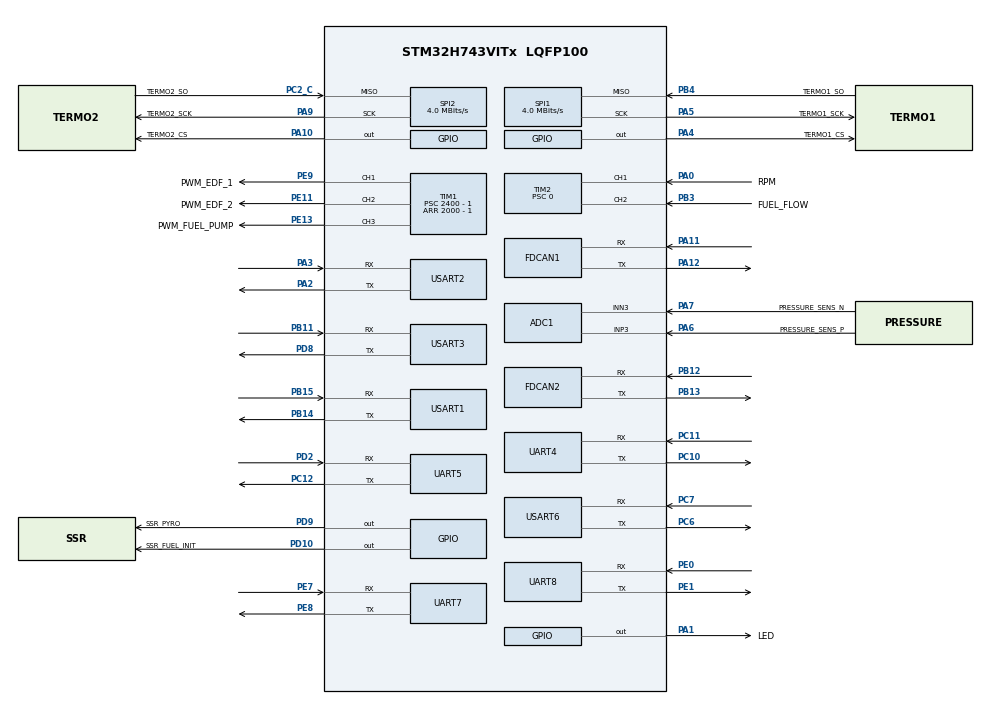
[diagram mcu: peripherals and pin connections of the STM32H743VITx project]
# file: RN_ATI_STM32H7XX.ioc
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ADC1.AutoInjectedConv-ADC_Injected_ConversionMode=DISABLE
ADC1.Channel-1\#ChannelRegularConversion=ADC_CHANNEL_3
ADC1.NbrOfConversionFlag=1
ADC1.OffsetNumber-1\#ChannelRegularConversion=ADC_OFFSET_NONE
ADC1.OffsetSignedSaturation-1\#ChannelRegularConversion=DISABLE
ADC1.Rank-1\#ChannelRegularConversion=1
ADC1.SamplingTime-1\#ChannelRegularConversion=ADC_SAMPLETIME_1CYCLE_5
ADC1.ScanConvMode-ADC_Settings=ADC_SCAN_ENABLE
ADC1.SingleDiff-1\#ChannelRegularConversion=ADC_DIFFERENTIAL_ENDED
ADC1.master=1
CORTEX_M7.default_mode_Activation=1
Dma.Request0=TIM1_CH1
Dma.Request1=TIM1_CH2
Dma.Request2=TIM1_CH3
Dma.TIM1_CH1.0.Direction=DMA_MEMORY_TO_PERIPH
Dma.TIM1_CH1.0.EventEnable=DISABLE
Dma.TIM1_CH1.0.FIFOMode=DMA_FIFOMODE_DISABLE
Dma.TIM1_CH1.0.Instance=DMA1_Stream0
Dma.TIM1_CH1.0.MemDataAlignment=DMA_MDATAALIGN_HALFWORD
Dma.TIM1_CH1.0.MemInc=DMA_MINC_ENABLE
Dma.TIM1_CH1.0.Mode=DMA_NORMAL
Dma.TIM1_CH1.0.PeriphDataAlignment=DMA_PDATAALIGN_HALFWORD
Dma.TIM1_CH1.0.PeriphInc=DMA_PINC_DISABLE
Dma.TIM1_CH1.0.Polarity=HAL_DMAMUX_REQ_GEN_RISING
Dma.TIM1_CH1.0.Priority=DMA_PRIORITY_LOW
Dma.TIM1_CH1.0.RequestNumber=1
Dma.TIM1_CH1.0.SignalID=NONE
Dma.TIM1_CH1.0.SyncEnable=DISABLE
Dma.TIM1_CH1.0.SyncPolarity=HAL_DMAMUX_SYNC_NO_EVENT
Dma.TIM1_CH1.0.SyncRequestNumber=1
Dma.TIM1_CH1.0.SyncSignalID=NONE
Dma.TIM1_CH2.1.Direction=DMA_MEMORY_TO_PERIPH
Dma.TIM1_CH2.1.EventEnable=DISABLE
Dma.TIM1_CH2.1.FIFOMode=DMA_FIFOMODE_DISABLE
Dma.TIM1_CH2.1.Instance=DMA1_Stream1
Dma.TIM1_CH2.1.MemDataAlignment=DMA_MDATAALIGN_HALFWORD
Dma.TIM1_CH2.1.MemInc=DMA_MINC_ENABLE
Dma.TIM1_CH2.1.Mode=DMA_NORMAL
Dma.TIM1_CH2.1.PeriphDataAlignment=DMA_PDATAALIGN_HALFWORD
Dma.TIM1_CH2.1.PeriphInc=DMA_PINC_DISABLE
Dma.TIM1_CH2.1.Polarity=HAL_DMAMUX_REQ_GEN_RISING
Dma.TIM1_CH2.1.Priority=DMA_PRIORITY_LOW
Dma.TIM1_CH2.1.RequestNumber=1
Dma.TIM1_CH2.1.SignalID=NONE
Dma.TIM1_CH2.1.SyncEnable=DISABLE
Dma.TIM1_CH2.1.SyncPolarity=HAL_DMAMUX_SYNC_NO_EVENT
Dma.TIM1_CH2.1.SyncRequestNumber=1
Dma.TIM1_CH2.1.SyncSignalID=NONE
Dma.TIM1_CH3.2.Direction=DMA_MEMORY_TO_PERIPH
Dma.TIM1_CH3.2.EventEnable=DISABLE
Dma.TIM1_CH3.2.FIFOMode=DMA_FIFOMODE_DISABLE
Dma.TIM1_CH3.2.Instance=DMA1_Stream2
Dma.TIM1_CH3.2.MemDataAlignment=DMA_MDATAALIGN_HALFWORD
Dma.TIM1_CH3.2.MemInc=DMA_MINC_ENABLE
Dma.TIM1_CH3.2.Mode=DMA_NORMAL
Dma.TIM1_CH3.2.PeriphDataAlignment=DMA_PDATAALIGN_HALFWORD
Dma.TIM1_CH3.2.PeriphInc=DMA_PINC_DISABLE
Dma.TIM1_CH3.2.Polarity=HAL_DMAMUX_REQ_GEN_RISING
Dma.TIM1_CH3.2.Priority=DMA_PRIORITY_LOW
Dma.TIM1_CH3.2.RequestNumber=1
Dma.TIM1_CH3.2.SignalID=NONE
Dma.TIM1_CH3.2.SyncEnable=DISABLE
Dma.TIM1_CH3.2.SyncPolarity=HAL_DMAMUX_SYNC_NO_EVENT
Dma.TIM1_CH3.2.SyncRequestNumber=1
Dma.TIM1_CH3.2.SyncSignalID=NONE
FDCAN1.CalculateBaudRateNominal=312500
FDCAN1.CalculateTimeBitNominal=3200
FDCAN1.CalculateTimeQuantumNominal=640.0
FDCAN2.CalculateBaudRateNominal=312500
FDCAN2.CalculateTimeBitNominal=3200
FDCAN2.CalculateTimeQuantumNominal=640.0
Mcu.Family=STM32H7
Mcu.Name=STM32H743VITx
Mcu.Package=LQFP100
NVIC.DMA1_Stream0_IRQn=true\:0\:0\:false\:false\:true\:false\:true\:true
NVIC.DMA1_Stream1_IRQn=true\:0\:0\:false\:false\:true\:false\:true\:true
NVIC.DMA1_Stream2_IRQn=true\:0\:0\:false\:false\:true\:false\:true\:true
NVIC.PriorityGroup=NVIC_PRIORITYGROUP_4
NVIC.SPI1_IRQn=true\:0\:0\:false\:false\:true\:true\:true\:true
NVIC.SPI2_IRQn=true\:0\:0\:false\:false\:true\:true\:true\:true
NVIC.TIM3_IRQn=true\:0\:0\:false\:false\:true\:true\:true\:true
PA0.GPIO_Label=RPM
PA0.GPIO_ModeDefaultPP=GPIO_MODE_AF_PP
PA0.GPIO_PuPd=GPIO_NOPULL
PA0.GPIO_Speed=GPIO_SPEED_FREQ_VERY_HIGH
PA0.Signal=S_TIM2_CH1_ETR
PA1.GPIO_Label=LED
PA1.Signal=GPIO_Output
PA10.GPIO_Label=TERMO2_CS
PA10.GPIO_Speed=GPIO_SPEED_FREQ_VERY_HIGH
PA10.PinAttribute=Free
PA10.PinState=GPIO_PIN_SET
PA10.Signal=GPIO_Output
PA11.Mode=FDCAN_Activate
PA11.PinAttribute=Free
PA11.Signal=FDCAN1_RX
PA12.Mode=FDCAN_Activate
PA12.PinAttribute=Free
PA12.Signal=FDCAN1_TX
PA13\ (JTMS/SWDIO).Mode=Serial_Wire
PA13\ (JTMS/SWDIO).PinAttribute=Free
PA13\ (JTMS/SWDIO).Signal=DEBUG_JTMS-SWDIO
PA14\ (JTCK/SWCLK).Mode=Serial_Wire
PA14\ (JTCK/SWCLK).PinAttribute=Free
PA14\ (JTCK/SWCLK).Signal=DEBUG_JTCK-SWCLK
PA2.GPIO_Speed=GPIO_SPEED_FREQ_VERY_HIGH
PA2.Mode=Asynchronous
PA2.PinAttribute=Free
PA2.Signal=USART2_TX
PA3.GPIO_Speed=GPIO_SPEED_FREQ_VERY_HIGH
PA3.Mode=Asynchronous
PA3.PinAttribute=Free
PA3.Signal=USART2_RX
PA4.GPIO_Label=TERMO1_CS
PA4.GPIO_Speed=GPIO_SPEED_FREQ_VERY_HIGH
PA4.PinAttribute=Free
PA4.PinState=GPIO_PIN_SET
PA4.Signal=GPIO_Output
PA5.GPIO_Label=TERMO1_SCK
PA5.GPIO_Speed=GPIO_SPEED_FREQ_VERY_HIGH
PA5.Mode=RX_Only_Simplex_Unidirect_Master
PA5.PinAttribute=Free
PA5.Signal=SPI1_SCK
PA6.GPIO_Label=PRESSURE_SENS_P
PA6.PinAttribute=Free
PA6.Signal=ADCx_INP3
PA7.GPIO_Label=PRESSURE_SENS_N
PA7.PinAttribute=Free
PA7.Signal=ADCx_INN3
PA9.GPIO_Label=TERMO2_SCK
PA9.GPIO_Speed=GPIO_SPEED_FREQ_VERY_HIGH
PA9.Mode=RX_Only_Simplex_Unidirect_Master
PA9.PinAttribute=Free
PA9.Signal=SPI2_SCK
PB11.GPIO_Speed=GPIO_SPEED_FREQ_VERY_HIGH
PB11.Mode=Asynchronous
PB11.PinAttribute=Free
PB11.Signal=USART3_RX
PB12.Mode=FDCAN_Activate
PB12.PinAttribute=Free
PB12.Signal=FDCAN2_RX
PB13.Mode=FDCAN_Activate
PB13.PinAttribute=Free
PB13.Signal=FDCAN2_TX
PB14.GPIO_Speed=GPIO_SPEED_FREQ_VERY_HIGH
PB14.Mode=Asynchronous
PB14.PinAttribute=Free
PB14.Signal=USART1_TX
PB15.GPIO_Speed=GPIO_SPEED_FREQ_VERY_HIGH
PB15.Mode=Asynchronous
PB15.PinAttribute=Free
PB15.Signal=USART1_RX
PB3\ (JTDO/TRACESWO).GPIO_Label=FUEL_FLOW
PB3\ (JTDO/TRACESWO).GPIO_ModeDefaultPP=GPIO_MODE_AF_PP
PB3\ (JTDO/TRACESWO).GPIO_PuPd=GPIO_NOPULL
PB3\ (JTDO/TRACESWO).GPIO_Speed=GPIO_SPEED_FREQ_VERY_HIGH
PB3\ (JTDO/TRACESWO).PinAttribute=Free
PB3\ (JTDO/TRACESWO).Signal=S_TIM2_CH2
PB4\ (NJTRST).GPIO_Label=TERMO1_SO
PB4\ (NJTRST).GPIO_Speed=GPIO_SPEED_FREQ_VERY_HIGH
PB4\ (NJTRST).Mode=RX_Only_Simplex_Unidirect_Master
PB4\ (NJTRST).PinAttribute=Free
PB4\ (NJTRST).Signal=SPI1_MISO
PC10.GPIO_Speed=GPIO_SPEED_FREQ_VERY_HIGH
PC10.Mode=Asynchronous
PC10.PinAttribute=Free
PC10.Signal=UART4_TX
PC11.GPIO_Speed=GPIO_SPEED_FREQ_VERY_HIGH
PC11.Mode=Asynchronous
PC11.PinAttribute=Free
PC11.Signal=UART4_RX
PC12.GPIO_Speed=GPIO_SPEED_FREQ_VERY_HIGH
PC12.Mode=Asynchronous
PC12.PinAttribute=Free
PC12.Signal=UART5_TX
PC14-OSC32_IN\ (OSC32_IN).Mode=LSE-External-Oscillator
PC14-OSC32_IN\ (OSC32_IN).Signal=RCC_OSC32_IN
PC15-OSC32_OUT\ (OSC32_OUT).Mode=LSE-External-Oscillator
PC15-OSC32_OUT\ (OSC32_OUT).Signal=RCC_OSC32_OUT
PC2_C.GPIO_Label=TERMO2_SO
PC2_C.GPIO_Speed=GPIO_SPEED_FREQ_VERY_HIGH
PC2_C.Mode=RX_Only_Simplex_Unidirect_Master
PC2_C.Signal=SPI2_MISO
PC6.GPIO_Speed=GPIO_SPEED_FREQ_VERY_HIGH
PC6.Mode=Asynchronous
PC6.PinAttribute=Free
PC6.Signal=USART6_TX
PC7.GPIO_Speed=GPIO_SPEED_FREQ_VERY_HIGH
PC7.Mode=Asynchronous
PC7.PinAttribute=Free
PC7.Signal=USART6_RX
PD10.GPIO_Label=SSR_FUEL_INIT
PD10.GPIO_Speed=GPIO_SPEED_FREQ_LOW
PD10.PinAttribute=Free
PD10.Signal=GPIO_Output
PD2.GPIO_Speed=GPIO_SPEED_FREQ_VERY_HIGH
PD2.Mode=Asynchronous
PD2.PinAttribute=Free
PD2.Signal=UART5_RX
PD8.GPIO_Speed=GPIO_SPEED_FREQ_VERY_HIGH
PD8.Mode=Asynchronous
PD8.PinAttribute=Free
PD8.Signal=USART3_TX
PD9.GPIO_Label=SSR_PYRO
PD9.PinAttribute=Free
PD9.Signal=GPIO_Output
PE0.GPIO_Speed=GPIO_SPEED_FREQ_VERY_HIGH
PE0.Mode=Asynchronous
PE0.Signal=UART8_RX
PE1.GPIO_Speed=GPIO_SPEED_FREQ_VERY_HIGH
PE1.Mode=Asynchronous
PE1.Signal=UART8_TX
PE11.GPIO_Label=PWM_EDF_2
PE11.GPIO_Speed=GPIO_SPEED_FREQ_VERY_HIGH
PE11.PinAttribute=Free
PE11.Signal=S_TIM1_CH2
PE13.GPIO_Label=PWM_FUEL_PUMP
PE13.GPIO_Speed=GPIO_SPEED_FREQ_VERY_HIGH
PE13.Signal=S_TIM1_CH3
PE7.GPIO_Speed=GPIO_SPEED_FREQ_VERY_HIGH
PE7.Mode=Asynchronous
PE7.PinAttribute=Free
PE7.Signal=UART7_RX
PE8.GPIO_Speed=GPIO_SPEED_FREQ_VERY_HIGH
PE8.Mode=Asynchronous
PE8.PinAttribute=Free
PE8.Signal=UART7_TX
PE9.GPIO_Label=PWM_EDF_1
PE9.GPIO_Speed=GPIO_SPEED_FREQ_VERY_HIGH
PE9.PinAttribute=Free
PE9.Signal=S_TIM1_CH1
PH0-OSC_IN\ (PH0).Mode=HSE-External-Oscillator
PH0-OSC_IN\ (PH0).Signal=RCC_OSC_IN
PH1-OSC_OUT\ (PH1).Mode=HSE-External-Oscillator
PH1-OSC_OUT\ (PH1).Signal=RCC_OSC_OUT
ProjectManager.HeapSize=0x200
ProjectManager.StackSize=0x400
ProjectManager.TargetToolchain=CMake
RCC.ADCFreq_Value=75000000
RCC.APB1Freq_Value=120000000
RCC.APB2Freq_Value=120000000
RCC.APB3Freq_Value=120000000
RCC.APB4Freq_Value=120000000
RCC.CortexFreq_Value=480000000
RCC.D1PPRE=RCC_APB3_DIV2
RCC.D2PPRE1=RCC_APB1_DIV2
RCC.D2PPRE2=RCC_APB2_DIV2
RCC.D3PPRE=RCC_APB4_DIV2
RCC.DIVM1=5
RCC.DIVM2=2
RCC.DIVN1=192
RCC.DIVN2=12
RCC.DIVQ1=5
RCC.EnbaleCSS=false
RCC.FDCANCLockSelection=RCC_FDCANCLKSOURCE_HSE
RCC.FLatency-AdvancedSettings=FLASH_LATENCY_2
RCC.HCLKFreq_Value=240000000
RCC.HPRE=RCC_HCLK_DIV2
RCC.PLL1_VCI_Range-AdvancedSettings=RCC_PLL1VCIRANGE_0
RCC.PLL2FRACN=0
RCC.PLL2_VCI_Range-AdvancedSettings=RCC_PLL2VCIRANGE_0
RCC.PLL3FRACN=0
RCC.PLL3_VCI_Range-AdvancedSettings=RCC_PLL3VCIRANGE_1
RCC.PLL3_VCO_SEL-AdvancedSettings=RCC_PLL3VCOMEDIUM
RCC.PLLFRACN=0
RCC.PLLSourceVirtual=RCC_PLLSOURCE_HSE
RCC.SPI123CLockSelection=RCC_SPI123CLKSOURCE_CLKP
RCC.SYSCLKFreq_VALUE=480000000
RCC.SYSCLKSource=RCC_SYSCLKSOURCE_PLLCLK
RCC.USBFreq_Value=192000000
SH.ADCx_INN3.0=ADC1_INN3,IN3-Differential
SH.ADCx_INP3.0=ADC1_INP3,IN3-Differential
SH.S_TIM1_CH1.0=TIM1_CH1,PWM Generation1 CH1
SH.S_TIM1_CH2.0=TIM1_CH2,PWM Generation2 CH2
SH.S_TIM1_CH3.0=TIM1_CH3,PWM Generation3 CH3
SH.S_TIM2_CH1_ETR.0=TIM2_CH1,Input_Capture1_from_TI1
SH.S_TIM2_CH2.0=TIM2_CH2,Input_Capture2_from_TI2
SPI1.BaudRatePrescaler=SPI_BAUDRATEPRESCALER_16
SPI1.CalculateBaudRate=4.0 MBits/s
SPI1.DataSize=SPI_DATASIZE_16BIT
SPI1.Direction=SPI_DIRECTION_2LINES_RXONLY
SPI1.Mode=SPI_MODE_MASTER
SPI1.VirtualType=VM_MASTER
SPI2.BaudRatePrescaler=SPI_BAUDRATEPRESCALER_16
SPI2.CalculateBaudRate=4.0 MBits/s
SPI2.DataSize=SPI_DATASIZE_16BIT
SPI2.Direction=SPI_DIRECTION_2LINES_RXONLY
SPI2.Mode=SPI_MODE_MASTER
SPI2.VirtualType=VM_MASTER
TIM1.Channel-Input_Capture1_from_TI1=TIM_CHANNEL_1
TIM1.Channel-Input_Capture2_from_TI2=TIM_CHANNEL_2
TIM1.Channel-PWM\ Generation1\ CH1=TIM_CHANNEL_1
TIM1.Channel-PWM\ Generation2\ CH2=TIM_CHANNEL_2
TIM1.Channel-PWM\ Generation3\ CH3=TIM_CHANNEL_3
TIM1.Period=2000 - 1
TIM1.Prescaler=2400 - 1
TIM2.Channel-Input_Capture1_from_TI1=TIM_CHANNEL_1
TIM2.Channel-Input_Capture2_from_TI2=TIM_CHANNEL_2
TIM2.Channel-PWM\ Generation1\ CH1=TIM_CHANNEL_1
TIM2.Channel-PWM\ Generation2\ CH2=TIM_CHANNEL_2
TIM2.Channel-PWM\ Generation3\ CH3=TIM_CHANNEL_3
TIM2.Period=23999999
TIM2.Prescaler=0
TIM3.Period=500 - 1
TIM3.Prescaler=24000 - 1
USART1.VirtualMode-Asynchronous=VM_ASYNC
USART2.VirtualMode-Asynchronous=VM_ASYNC
USART3.VirtualMode-Asynchronous=VM_ASYNC
USART6.VirtualMode=VM_ASYNC
VP_MEMORYMAP_VS_MEMORYMAP.Mode=CurAppReg
VP_TIM1_VS_ClockSourceINT.Mode=Internal
VP_TIM2_VS_ClockSourceINT.Mode=Internal
VP_TIM3_VS_ClockSourceINT.Mode=Internal
board=custom

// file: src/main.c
/* USER CODE BEGIN Header */
/**
  ******************************************************************************
  * @file           : main.c
  * @brief          : Main program body
  ******************************************************************************
  * @attention
  *
  * Copyright (c) 2024 STMicroelectronics.
  * All rights reserved.
  *
  * This software is licensed under terms that can be found in the LICENSE file
  * in the root directory of this software component.
  * If no LICENSE file comes with this software, it is provided AS-IS.
  *
  ******************************************************************************
  */
/* USER CODE END Header */
#include "main.h"
#include "adc.h"
#include "dma.h"
#include "fdcan.h"
#include "memorymap.h"
#include "spi.h"
#include "tim.h"
#include "usart.h"
#include "gpio.h"

/* USER CODE BEGIN Includes */
#include "pwm_control.h"
/* USER CODE END Includes */

void SystemClock_Config(void);
void PeriphCommonClock_Config(void);
static void MPU_Config(void);

int main(void)
{

  /* MPU Configuration--------------------------------------------------------*/
  MPU_Config();

  /* MCU Configuration--------------------------------------------------------*/

  /* Reset of all peripherals, Initializes the Flash interface and the Systick. */
  HAL_Init();

  /* Configure the system clock */
  SystemClock_Config();

  /* Configure the peripherals common clocks */
  PeriphCommonClock_Config();

  /* Initialize all configured peripherals */
  MX_GPIO_Init();
  MX_DMA_Init();
  MX_ADC1_Init();
  MX_FDCAN1_Init();
  MX_FDCAN2_Init();
  MX_SPI1_Init();
  MX_SPI2_Init();
  MX_TIM1_Init();
  MX_TIM2_Init();
  MX_UART4_Init();
  MX_UART5_Init();
  MX_UART7_Init();
  MX_UART8_Init();
  MX_USART1_UART_Init();
  MX_USART2_UART_Init();
  MX_USART3_UART_Init();
  MX_USART6_UART_Init();
  MX_TIM3_Init();
  /* USER CODE BEGIN 2 */
  HAL_TIM_PWM_Start(&htim1, TIM_CHANNEL_1);  /* USER CODE END 2 */
  uint16_t pulseWidth = 100;   // Nilai awal 1000 µs (throttle minimum)
  /* Infinite loop */
  while (1)
  {
    GPIO_PinState LED_state = HAL_GPIO_ReadPin(GPIOE,GPIO_PIN_3);
      if (LED_state == GPIO_PIN_RESET)  // GPIO input LOW
      {
          if (pulseWidth < 200)
          {
              pulseWidth += 1;  // Tingkatkan nilai pulseWidth sebesar 1 µs
              HAL_Delay(100);    // Delay 10 ms untuk perubahan yang lebih lambat
          }
      }
      else{
          pulseWidth = 100;
      }
      // Set nilai duty cycle dengan nilai pulseWidth yang terhitung
    SetPWMDutyCycle(&htim1, TIM_CHANNEL_1,pulseWidth);
  }
}
void SystemClock_Config(void)
{
  RCC_OscInitTypeDef RCC_OscInitStruct = {0};
  RCC_ClkInitTypeDef RCC_ClkInitStruct = {0};

  /** Supply configuration update enable
  */
  HAL_PWREx_ConfigSupply(PWR_LDO_SUPPLY);

  /** Configure the main internal regulator output voltage
  */
  __HAL_PWR_VOLTAGESCALING_CONFIG(PWR_REGULATOR_VOLTAGE_SCALE1);

  while(!__HAL_PWR_GET_FLAG(PWR_FLAG_VOSRDY)) {}

  __HAL_RCC_SYSCFG_CLK_ENABLE();
  __HAL_PWR_VOLTAGESCALING_CONFIG(PWR_REGULATOR_VOLTAGE_SCALE0);

  while(!__HAL_PWR_GET_FLAG(PWR_FLAG_VOSRDY)) {}

  /** Initializes the RCC Oscillators according to the specified parameters
  * in the RCC_OscInitTypeDef structure.
  */
  RCC_OscInitStruct.OscillatorType = RCC_OSCILLATORTYPE_HSI|RCC_OSCILLATORTYPE_HSE;
  RCC_OscInitStruct.HSEState = RCC_HSE_ON;
  RCC_OscInitStruct.HSIState = RCC_HSI_DIV1;
  RCC_OscInitStruct.HSICalibrationValue = RCC_HSICALIBRATION_DEFAULT;
  RCC_OscInitStruct.PLL.PLLState = RCC_PLL_ON;
  RCC_OscInitStruct.PLL.PLLSource = RCC_PLLSOURCE_HSE;
  RCC_OscInitStruct.PLL.PLLM = 5;
  RCC_OscInitStruct.PLL.PLLN = 192;
  RCC_OscInitStruct.PLL.PLLP = 2;
  RCC_OscInitStruct.PLL.PLLQ = 5;
  RCC_OscInitStruct.PLL.PLLR = 2;
  RCC_OscInitStruct.PLL.PLLRGE = RCC_PLL1VCIRANGE_2;
  RCC_OscInitStruct.PLL.PLLVCOSEL = RCC_PLL1VCOWIDE;
  RCC_OscInitStruct.PLL.PLLFRACN = 0;
  if (HAL_RCC_OscConfig(&RCC_OscInitStruct) != HAL_OK)
  {
    Error_Handler();
  }

  /** Initializes the CPU, AHB and APB buses clocks
  */
  RCC_ClkInitStruct.ClockType = RCC_CLOCKTYPE_HCLK|RCC_CLOCKTYPE_SYSCLK
                              |RCC_CLOCKTYPE_PCLK1|RCC_CLOCKTYPE_PCLK2
                              |RCC_CLOCKTYPE_D3PCLK1|RCC_CLOCKTYPE_D1PCLK1;
  RCC_ClkInitStruct.SYSCLKSource = RCC_SYSCLKSOURCE_PLLCLK;
  RCC_ClkInitStruct.SYSCLKDivider = RCC_SYSCLK_DIV1;
  RCC_ClkInitStruct.AHBCLKDivider = RCC_HCLK_DIV2;
  RCC_ClkInitStruct.APB3CLKDivider = RCC_APB3_DIV2;
  RCC_ClkInitStruct.APB1CLKDivider = RCC_APB1_DIV2;
  RCC_ClkInitStruct.APB2CLKDivider = RCC_APB2_DIV2;
  RCC_ClkInitStruct.APB4CLKDivider = RCC_APB4_DIV2;

  if (HAL_RCC_ClockConfig(&RCC_ClkInitStruct, FLASH_LATENCY_4) != HAL_OK)
  {
    Error_Handler();
  }
}

void PeriphCommonClock_Config(void)
{
  RCC_PeriphCLKInitTypeDef PeriphClkInitStruct = {0};

  /** Initializes the peripherals clock
  */
  PeriphClkInitStruct.PeriphClockSelection = RCC_PERIPHCLK_CKPER;
  PeriphClkInitStruct.CkperClockSelection = RCC_CLKPSOURCE_HSI;
  if (HAL_RCCEx_PeriphCLKConfig(&PeriphClkInitStruct) != HAL_OK)
  {
    Error_Handler();
  }
}

 /* MPU Configuration */

void MPU_Config(void)
{
  MPU_Region_InitTypeDef MPU_InitStruct = {0};

  /* Disables the MPU */
  HAL_MPU_Disable();

  /** Initializes and configures the Region and the memory to be protected
  */
  MPU_InitStruct.Enable = MPU_REGION_ENABLE;
  MPU_InitStruct.Number = MPU_REGION_NUMBER0;
  MPU_InitStruct.BaseAddress = 0x0;
  MPU_InitStruct.Size = MPU_REGION_SIZE_4GB;
  MPU_InitStruct.SubRegionDisable = 0x87;
  MPU_InitStruct.TypeExtField = MPU_TEX_LEVEL0;
  MPU_InitStruct.AccessPermission = MPU_REGION_NO_ACCESS;
  MPU_InitStruct.DisableExec = MPU_INSTRUCTION_ACCESS_DISABLE;
  MPU_InitStruct.IsShareable = MPU_ACCESS_SHAREABLE;
  MPU_InitStruct.IsCacheable = MPU_ACCESS_NOT_CACHEABLE;
  MPU_InitStruct.IsBufferable = MPU_ACCESS_NOT_BUFFERABLE;

  HAL_MPU_ConfigRegion(&MPU_InitStruct);
  /* Enables the MPU */
  HAL_MPU_Enable(MPU_PRIVILEGED_DEFAULT);

}

void Error_Handler(void)
{
  __disable_irq();
  while (1)
  {
  }
}
